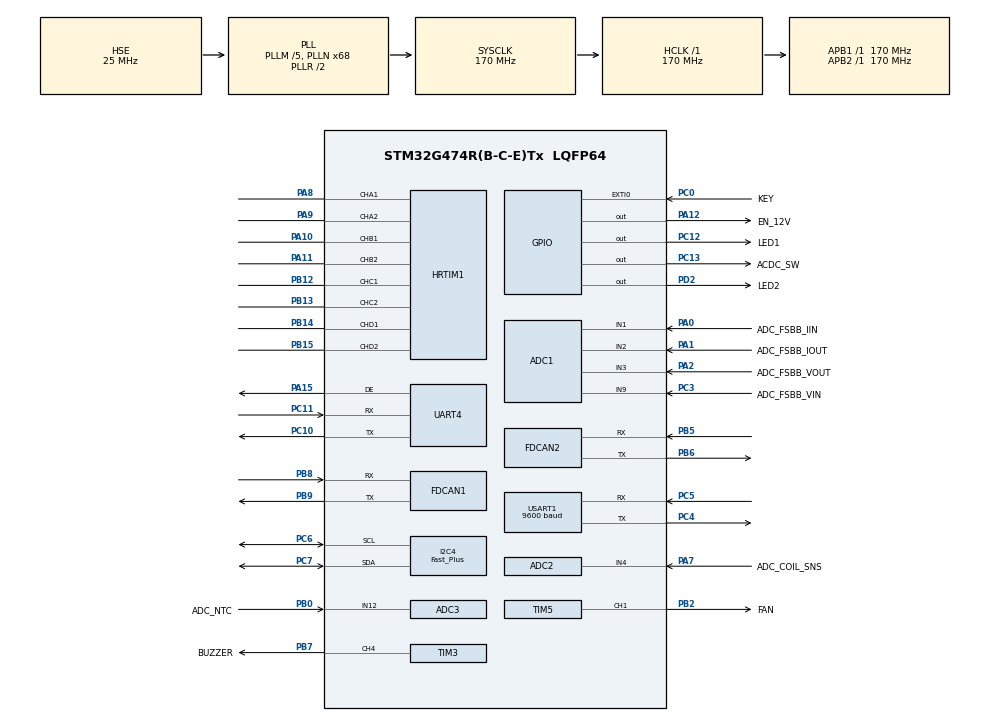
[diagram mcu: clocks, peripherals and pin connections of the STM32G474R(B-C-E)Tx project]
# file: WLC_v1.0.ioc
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ADC1.Channel-0\#ChannelRegularConversion=ADC_CHANNEL_9
ADC1.Channel-1\#ChannelRegularConversion=ADC_CHANNEL_3
ADC1.Channel-2\#ChannelRegularConversion=ADC_CHANNEL_1
ADC1.Channel-3\#ChannelRegularConversion=ADC_CHANNEL_2
ADC1.Channel-4\#ChannelRegularConversion=ADC_CHANNEL_9
ADC1.Channel-5\#ChannelRegularConversion=ADC_CHANNEL_3
ADC1.Channel-6\#ChannelRegularConversion=ADC_CHANNEL_1
ADC1.Channel-7\#ChannelRegularConversion=ADC_CHANNEL_2
ADC1.ContinuousConvMode=ENABLE
ADC1.DMAContinuousRequests=ENABLE
ADC1.EOCSelection=ADC_EOC_SEQ_CONV
ADC1.ExternalTrigConv=ADC_EXTERNALTRIG_HRTIM_TRG3
ADC1.ExternalTrigConvEdge=ADC_EXTERNALTRIGCONVEDGE_RISINGFALLING
ADC1.NbrOfConversion=8
ADC1.NbrOfConversionFlag=1
ADC1.OffsetNumber-0\#ChannelRegularConversion=ADC_OFFSET_NONE
ADC1.OffsetNumber-1\#ChannelRegularConversion=ADC_OFFSET_NONE
ADC1.OffsetNumber-2\#ChannelRegularConversion=ADC_OFFSET_NONE
ADC1.OffsetNumber-3\#ChannelRegularConversion=ADC_OFFSET_NONE
ADC1.OffsetNumber-4\#ChannelRegularConversion=ADC_OFFSET_NONE
ADC1.OffsetNumber-5\#ChannelRegularConversion=ADC_OFFSET_NONE
ADC1.OffsetNumber-6\#ChannelRegularConversion=ADC_OFFSET_NONE
ADC1.OffsetNumber-7\#ChannelRegularConversion=ADC_OFFSET_NONE
ADC1.Overrun=ADC_OVR_DATA_OVERWRITTEN
ADC1.OversamplingMode=ENABLE
ADC1.Rank-0\#ChannelRegularConversion=1
ADC1.Rank-1\#ChannelRegularConversion=2
ADC1.Rank-2\#ChannelRegularConversion=3
ADC1.Rank-3\#ChannelRegularConversion=4
ADC1.Rank-4\#ChannelRegularConversion=5
ADC1.Rank-5\#ChannelRegularConversion=6
ADC1.Rank-6\#ChannelRegularConversion=7
ADC1.Rank-7\#ChannelRegularConversion=8
ADC1.Ratio=ADC_OVERSAMPLING_RATIO_16
ADC1.SamplingTime-0\#ChannelRegularConversion=ADC_SAMPLETIME_2CYCLES_5
ADC1.SamplingTime-1\#ChannelRegularConversion=ADC_SAMPLETIME_2CYCLES_5
ADC1.SamplingTime-2\#ChannelRegularConversion=ADC_SAMPLETIME_2CYCLES_5
ADC1.SamplingTime-3\#ChannelRegularConversion=ADC_SAMPLETIME_2CYCLES_5
ADC1.SamplingTime-4\#ChannelRegularConversion=ADC_SAMPLETIME_2CYCLES_5
ADC1.SamplingTime-5\#ChannelRegularConversion=ADC_SAMPLETIME_2CYCLES_5
ADC1.SamplingTime-6\#ChannelRegularConversion=ADC_SAMPLETIME_2CYCLES_5
ADC1.SamplingTime-7\#ChannelRegularConversion=ADC_SAMPLETIME_2CYCLES_5
ADC1.master=1
ADC2.Channel-0\#ChannelRegularConversion=ADC_CHANNEL_4
ADC2.Channel-1\#ChannelRegularConversion=ADC_CHANNEL_4
ADC2.ContinuousConvMode=ENABLE
ADC2.DMAContinuousRequests=ENABLE
ADC2.ExternalTrigConv=ADC_EXTERNALTRIG_HRTIM_TRG3
ADC2.ExternalTrigConvEdge=ADC_EXTERNALTRIGCONVEDGE_RISINGFALLING
ADC2.NbrOfConversion=2
ADC2.NbrOfConversionFlag=1
ADC2.OffsetNumber-0\#ChannelRegularConversion=ADC_OFFSET_NONE
ADC2.OffsetNumber-1\#ChannelRegularConversion=ADC_OFFSET_NONE
ADC2.Overrun=ADC_OVR_DATA_OVERWRITTEN
ADC2.OversamplingMode=ENABLE
ADC2.Rank-0\#ChannelRegularConversion=1
ADC2.Rank-1\#ChannelRegularConversion=2
ADC2.Ratio=ADC_OVERSAMPLING_RATIO_16
ADC2.SamplingTime-0\#ChannelRegularConversion=ADC_SAMPLETIME_2CYCLES_5
ADC2.SamplingTime-1\#ChannelRegularConversion=ADC_SAMPLETIME_2CYCLES_5
ADC3.Channel-0\#ChannelRegularConversion=ADC_CHANNEL_12
ADC3.Channel-1\#ChannelRegularConversion=ADC_CHANNEL_12
ADC3.ContinuousConvMode=ENABLE
ADC3.DMAContinuousRequests=ENABLE
ADC3.EOCSelection=ADC_EOC_SEQ_CONV
ADC3.ExternalTrigConv=ADC_EXTERNALTRIG_HRTIM_TRG3
ADC3.ExternalTrigConvEdge=ADC_EXTERNALTRIGCONVEDGE_RISINGFALLING
ADC3.NbrOfConversion=2
ADC3.NbrOfConversionFlag=1
ADC3.OffsetNumber-0\#ChannelRegularConversion=ADC_OFFSET_NONE
ADC3.OffsetNumber-1\#ChannelRegularConversion=ADC_OFFSET_NONE
ADC3.Overrun=ADC_OVR_DATA_OVERWRITTEN
ADC3.OversamplingMode=ENABLE
ADC3.Rank-0\#ChannelRegularConversion=1
ADC3.Rank-1\#ChannelRegularConversion=2
ADC3.Ratio=ADC_OVERSAMPLING_RATIO_16
ADC3.SamplingTime-0\#ChannelRegularConversion=ADC_SAMPLETIME_2CYCLES_5
ADC3.SamplingTime-1\#ChannelRegularConversion=ADC_SAMPLETIME_2CYCLES_5
ADC3.master=1
Dma.ADC1.0.Direction=DMA_PERIPH_TO_MEMORY
Dma.ADC1.0.EventEnable=DISABLE
Dma.ADC1.0.Instance=DMA1_Channel1
Dma.ADC1.0.MemDataAlignment=DMA_MDATAALIGN_HALFWORD
Dma.ADC1.0.MemInc=DMA_MINC_ENABLE
Dma.ADC1.0.Mode=DMA_CIRCULAR
Dma.ADC1.0.PeriphDataAlignment=DMA_PDATAALIGN_HALFWORD
Dma.ADC1.0.PeriphInc=DMA_PINC_DISABLE
Dma.ADC1.0.Polarity=HAL_DMAMUX_REQ_GEN_RISING
Dma.ADC1.0.Priority=DMA_PRIORITY_VERY_HIGH
Dma.ADC1.0.RequestNumber=1
Dma.ADC1.0.SignalID=NONE
Dma.ADC1.0.SyncEnable=DISABLE
Dma.ADC1.0.SyncPolarity=HAL_DMAMUX_SYNC_NO_EVENT
Dma.ADC1.0.SyncRequestNumber=1
Dma.ADC1.0.SyncSignalID=NONE
Dma.ADC2.2.Direction=DMA_PERIPH_TO_MEMORY
Dma.ADC2.2.EventEnable=DISABLE
Dma.ADC2.2.Instance=DMA1_Channel3
Dma.ADC2.2.MemDataAlignment=DMA_MDATAALIGN_HALFWORD
Dma.ADC2.2.MemInc=DMA_MINC_ENABLE
Dma.ADC2.2.Mode=DMA_CIRCULAR
Dma.ADC2.2.PeriphDataAlignment=DMA_PDATAALIGN_HALFWORD
Dma.ADC2.2.PeriphInc=DMA_PINC_DISABLE
Dma.ADC2.2.Polarity=HAL_DMAMUX_REQ_GEN_RISING
Dma.ADC2.2.Priority=DMA_PRIORITY_VERY_HIGH
Dma.ADC2.2.RequestNumber=1
Dma.ADC2.2.SignalID=NONE
Dma.ADC2.2.SyncEnable=DISABLE
Dma.ADC2.2.SyncPolarity=HAL_DMAMUX_SYNC_NO_EVENT
Dma.ADC2.2.SyncRequestNumber=1
Dma.ADC2.2.SyncSignalID=NONE
Dma.ADC3.1.Direction=DMA_PERIPH_TO_MEMORY
Dma.ADC3.1.EventEnable=DISABLE
Dma.ADC3.1.Instance=DMA1_Channel2
Dma.ADC3.1.MemDataAlignment=DMA_MDATAALIGN_HALFWORD
Dma.ADC3.1.MemInc=DMA_MINC_ENABLE
Dma.ADC3.1.Mode=DMA_CIRCULAR
Dma.ADC3.1.PeriphDataAlignment=DMA_PDATAALIGN_HALFWORD
Dma.ADC3.1.PeriphInc=DMA_PINC_DISABLE
Dma.ADC3.1.Polarity=HAL_DMAMUX_REQ_GEN_RISING
Dma.ADC3.1.Priority=DMA_PRIORITY_LOW
Dma.ADC3.1.RequestNumber=1
Dma.ADC3.1.SignalID=NONE
Dma.ADC3.1.SyncEnable=DISABLE
Dma.ADC3.1.SyncPolarity=HAL_DMAMUX_SYNC_NO_EVENT
Dma.ADC3.1.SyncRequestNumber=1
Dma.ADC3.1.SyncSignalID=NONE
Dma.Request0=ADC1
Dma.Request1=ADC3
Dma.Request2=ADC2
FDCAN1.CalculateBaudRateNominal=3541666
FDCAN1.CalculateTimeBitNominal=282
FDCAN1.CalculateTimeQuantumNominal=94.11764705882354
FDCAN2.CalculateBaudRateNominal=3541666
FDCAN2.CalculateTimeBitNominal=282
FDCAN2.CalculateTimeQuantumNominal=94.11764705882354
HRTIM1.ADCTrigger1_Source1=HRTIM_ADCTRIGGEREVENT13_MASTER_CMP1
HRTIM1.ADCTrigger3_Source1=HRTIM_ADCTRIGGEREVENT13_MASTER_CMP3
HRTIM1.ADCTrigger_Id1=HRTIM_ADCTRIGGER_1
HRTIM1.ADCTrigger_Id2=__NULL
HRTIM1.ADCTrigger_Id3=HRTIM_ADCTRIGGER_3
HRTIM1.CompareUnit1-MasterTimer=HRTIM_COMPAREUNIT_1
HRTIM1.CompareUnit1-Output_TA1TA2=HRTIM_COMPAREUNIT_1
HRTIM1.CompareUnit1-Output_TB1TB2=HRTIM_COMPAREUNIT_1
HRTIM1.CompareUnit1-Output_TC1TC2=HRTIM_COMPAREUNIT_1
HRTIM1.CompareUnit1-Output_TD1TD2=HRTIM_COMPAREUNIT_1
HRTIM1.CompareUnit2-MasterTimer=__NULL
HRTIM1.CompareUnit2-Output_TA1TA2=__NULL
HRTIM1.CompareUnit2-Output_TB1TB2=HRTIM_COMPAREUNIT_2
HRTIM1.CompareUnit2-Output_TC1TC2=HRTIM_COMPAREUNIT_2
HRTIM1.CompareUnit2-Output_TD1TD2=__NULL
HRTIM1.CompareUnit3-MasterTimer=HRTIM_COMPAREUNIT_3
HRTIM1.CompareUnit3-Output_TA1TA2=HRTIM_COMPAREUNIT_3
HRTIM1.CompareUnit3-Output_TB1TB2=HRTIM_COMPAREUNIT_3
HRTIM1.CompareUnit3-Output_TC1TC2=HRTIM_COMPAREUNIT_3
HRTIM1.CompareUnit3-Output_TD1TD2=HRTIM_COMPAREUNIT_3
HRTIM1.CompareUnit4-MasterTimer=__NULL
HRTIM1.CompareUnit4-Output_TD1TD2=__NULL
HRTIM1.CompareValue1-MasterTimer=0
HRTIM1.CompareValue1-Output_TC1TC2=0xFFDF
HRTIM1.CompareValue1-Output_TD1TD2=0xFFDF
HRTIM1.CompareValue2-Output_TB1TB2=PERIOD_FSBB / 2
HRTIM1.CompareValue2-Output_TC1TC2=PERIOD_LCC/2
HRTIM1.CompareValue3-MasterTimer=PERIOD_MASTERTIMER / 2
HRTIM1.CompareValue3-Output_TB1TB2=0xFFDF
HRTIM1.DeadTimeInsertion-Output_TA1TA2=HRTIM_TIMDEADTIMEINSERTION_ENABLED
HRTIM1.DeadTimeInsertion-Output_TB1TB2=HRTIM_TIMDEADTIMEINSERTION_ENABLED
HRTIM1.DeadTimeInsertion-Output_TC1TC2=HRTIM_TIMDEADTIMEINSERTION_ENABLED
HRTIM1.DeadTimeInsertion-Output_TD1TD2=HRTIM_TIMDEADTIMEINSERTION_ENABLED
HRTIM1.FallingValue-Output_TA1TA2=DeathTime_FSBB
HRTIM1.FallingValue-Output_TB1TB2=DeathTime_FSBB
HRTIM1.FallingValue-Output_TC1TC2=DeathTime_LCC
HRTIM1.FallingValue-Output_TD1TD2=DeathTime_LCC
HRTIM1.FaultLevel1-Output_TC1TC2=HRTIM_OUTPUTFAULTLEVEL_INACTIVE
HRTIM1.FaultLevel1-Output_TD1TD2=HRTIM_OUTPUTFAULTLEVEL_INACTIVE
HRTIM1.FaultLevel2-Output_TC1TC2=HRTIM_OUTPUTFAULTLEVEL_INACTIVE
HRTIM1.FaultLevel2-Output_TD1TD2=HRTIM_OUTPUTFAULTLEVEL_INACTIVE
HRTIM1.InterruptRequests1_Master=HRTIM_MASTER_IT_MREP
HRTIM1.NumberADCTriggerSource1=1
HRTIM1.NumberADCTriggerSource3=1
HRTIM1.NumberFaultEnable-Output_TC1TC2=0
HRTIM1.NumberFaultEnable-Output_TD1TD2=0
HRTIM1.NumberInterruptRequests-Output_TC1TC2=0
HRTIM1.NumberInterruptRequests_Master-MasterTimer=1
HRTIM1.NumberResetSource1-Output_TA1TA2=1
HRTIM1.NumberResetSource1-Output_TB1TB2=1
HRTIM1.NumberResetSource1-Output_TC1TC2=1
HRTIM1.NumberResetSource1-Output_TD1TD2=1
HRTIM1.NumberResetSource2_TC=0
HRTIM1.NumberResetTrigger-Output_TA1TA2=1
HRTIM1.NumberResetTrigger-Output_TB1TB2=1
HRTIM1.NumberResetTrigger-Output_TC1TC2=1
HRTIM1.NumberResetTrigger-Output_TD1TD2=1
HRTIM1.NumberSetSource1-Output_TA1TA2=1
HRTIM1.NumberSetSource1-Output_TB1TB2=1
HRTIM1.NumberSetSource1-Output_TC1TC2=1
HRTIM1.NumberSetSource1-Output_TD1TD2=1
HRTIM1.NumberUpdateTrigger-Output_TA1TA2=1
HRTIM1.NumberUpdateTrigger-Output_TC1TC2=1
HRTIM1.NumberUpdateTrigger-Output_TD1TD2=1
HRTIM1.Periode_MASTER=PERIOD_MASTERTIMER
HRTIM1.Periode_TA=PERIOD_FSBB
HRTIM1.Periode_TB=PERIOD_FSBB
HRTIM1.Periode_TC=PERIOD_LCC
HRTIM1.Periode_TD=PERIOD_LCC
HRTIM1.Polarity1-Output_TA1TA2=HRTIM_OUTPUTPOLARITY_HIGH
HRTIM1.Polarity1-Output_TC1TC2=HRTIM_OUTPUTPOLARITY_HIGH
HRTIM1.Polarity1-Output_TD1TD2=HRTIM_OUTPUTPOLARITY_HIGH
HRTIM1.Polarity2-Output_TC1TC2=HRTIM_OUTPUTPOLARITY_HIGH
HRTIM1.Polarity2-Output_TD1TD2=HRTIM_OUTPUTPOLARITY_HIGH
HRTIM1.PreloadEnable-MasterTimer=HRTIM_PRELOAD_ENABLED
HRTIM1.PreloadEnable-Output_TA1TA2=HRTIM_PRELOAD_ENABLED
HRTIM1.PreloadEnable-Output_TB1TB2=HRTIM_PRELOAD_ENABLED
HRTIM1.PreloadEnable-Output_TC1TC2=HRTIM_PRELOAD_ENABLED
HRTIM1.PreloadEnable-Output_TD1TD2=HRTIM_PRELOAD_ENABLED
HRTIM1.ReSyncUpdate-Output_TC1TC2=HRTIM_TIMERESYNC_UPDATE_CONDITIONAL
HRTIM1.RepetitionCounter-MasterTimer=0
HRTIM1.RepetitionUpdate-MasterTimer=HRTIM_UPDATEONREPETITION_ENABLED
HRTIM1.RepetitionUpdate-Output_TA1TA2=HRTIM_UPDATEONREPETITION_ENABLED
HRTIM1.RepetitionUpdate-Output_TC1TC2=HRTIM_UPDATEONREPETITION_ENABLED
HRTIM1.RepetitionUpdate-Output_TD1TD2=HRTIM_UPDATEONREPETITION_ENABLED
HRTIM1.ResetOutput1_Source1-Output_TA1TA2=HRTIM_OUTPUTRESET_TIMCMP3
HRTIM1.ResetOutput1_Source1-Output_TB1TB2=HRTIM_OUTPUTRESET_TIMCMP3
HRTIM1.ResetOutput1_Source1-Output_TC1TC2=HRTIM_OUTPUTRESET_TIMCMP1
HRTIM1.ResetOutput1_Source1-Output_TD1TD2=HRTIM_OUTPUTRESET_TIMCMP1
HRTIM1.ResetTrigger1-Output_TA1TA2=HRTIM_TIMRESETTRIGGER_MASTER_CMP1
HRTIM1.ResetTrigger1-Output_TB1TB2=HRTIM_TIMRESETTRIGGER_MASTER_CMP1
HRTIM1.ResetTrigger1-Output_TC1TC2=HRTIM_TIMRESETTRIGGER_MASTER_CMP1
HRTIM1.ResetTrigger1-Output_TD1TD2=HRTIM_TIMRESETTRIGGER_OTHER3_CMP2
HRTIM1.ResetUpdate-Output_TA1TA2=HRTIM_TIMUPDATEONRESET_ENABLED
HRTIM1.ResetUpdate-Output_TB1TB2=HRTIM_TIMUPDATEONRESET_ENABLED
HRTIM1.ResetUpdate-Output_TC1TC2=HRTIM_TIMUPDATEONRESET_DISABLED
HRTIM1.ResetUpdate-Output_TD1TD2=HRTIM_TIMUPDATEONRESET_DISABLED
HRTIM1.RisingValue-Output_TA1TA2=DeathTime_FSBB
HRTIM1.RisingValue-Output_TB1TB2=DeathTime_FSBB
HRTIM1.RisingValue-Output_TC1TC2=DeathTime_LCC
HRTIM1.RisingValue-Output_TD1TD2=DeathTime_LCC
HRTIM1.SetOutput1_Source1-Output_TA1TA2=HRTIM_OUTPUTSET_TIMCMP1
HRTIM1.SetOutput1_Source1-Output_TB1TB2=HRTIM_OUTPUTSET_TIMCMP1
HRTIM1.SetOutput1_Source1-Output_TC1TC2=HRTIM_OUTPUTSET_TIMCMP3
HRTIM1.SetOutput1_Source1-Output_TD1TD2=HRTIM_OUTPUTSET_TIMCMP3
HRTIM1.SwapC=__NULL
HRTIM1.UpdateTrigger1-Output_TA1TA2=HRTIM_TIMUPDATETRIGGER_MASTER
HRTIM1.UpdateTrigger1-Output_TC1TC2=HRTIM_TIMUPDATETRIGGER_MASTER
HRTIM1.UpdateTrigger1-Output_TD1TD2=HRTIM_TIMUPDATETRIGGER_MASTER
HRTIM1.postscaler1=1
HRTIM1.postscaler3=10-1
I2C4.Analog_Filter=I2C_ANALOGFILTER_ENABLE
I2C4.I2C_Speed_Mode=I2C_Fast_Plus
I2C4.Timing=0x4052060F
Mcu.Family=STM32G4
Mcu.Name=STM32G474R(B-C-E)Tx
Mcu.Package=LQFP64
Mcu.UserConstants=PERIOD_LCC,47418;PERIOD_FSBB,27200;PERIOD_MASTERTIMER,13600;DeathTime_LCC,50;DeathTime_FSBB,30
NVIC.ADC1_2_IRQn=true\:0\:0\:false\:false\:true\:true\:true\:true
NVIC.ADC3_IRQn=true\:0\:0\:false\:false\:true\:true\:true\:true
NVIC.DMA1_Channel1_IRQn=true\:0\:0\:false\:false\:true\:false\:true\:true
NVIC.DMA1_Channel2_IRQn=true\:0\:0\:false\:false\:true\:false\:true\:true
NVIC.DMA1_Channel3_IRQn=true\:0\:0\:false\:false\:true\:false\:true\:true
NVIC.EXTI0_IRQn=true\:0\:0\:false\:false\:true\:true\:true\:true
NVIC.FDCAN2_IT0_IRQn=true\:0\:0\:false\:false\:true\:true\:true\:true
NVIC.FDCAN2_IT1_IRQn=true\:0\:0\:false\:false\:true\:true\:true\:true
NVIC.HRTIM1_Master_IRQn=true\:0\:0\:false\:false\:true\:true\:true\:true
NVIC.PriorityGroup=NVIC_PRIORITYGROUP_4
NVIC.TIM6_DAC_IRQn=true\:0\:0\:false\:false\:true\:true\:true\:true
NVIC.TIM7_DAC_IRQn=true\:0\:0\:false\:false\:true\:true\:true\:true
NVIC.USART1_IRQn=true\:0\:0\:false\:false\:true\:true\:true\:true
PA0.GPIO_Label=ADC_FSBB_IIN
PA0.Mode=IN1-Single-Ended
PA0.Signal=ADC1_IN1
PA1.GPIO_Label=ADC_FSBB_IOUT
PA1.Mode=IN2-Single-Ended
PA1.Signal=ADC1_IN2
PA10.GPIO_PuPd=GPIO_PULLDOWN
PA10.Mode=Output_TB1TB2
PA10.Signal=HRTIM1_CHB1
PA11.GPIO_PuPd=GPIO_PULLDOWN
PA11.Mode=Output_TB1TB2
PA11.Signal=HRTIM1_CHB2
PA12.GPIO_Label=EN_12V
PA12.GPIO_ModeDefaultOutputPP=GPIO_MODE_OUTPUT_OD
PA12.GPIO_PuPd=GPIO_NOPULL
PA12.PinState=GPIO_PIN_SET
PA12.Signal=GPIO_Output
PA13.Mode=Serial_Wire
PA13.Signal=SYS_JTMS-SWDIO
PA14.Mode=Serial_Wire
PA14.Signal=SYS_JTCK-SWCLK
PA15.Mode=Hardware Flow Control (RS485)
PA15.Signal=UART4_DE
PA2.GPIO_Label=ADC_FSBB_VOUT
PA2.Mode=IN3-Single-Ended
PA2.Signal=ADC1_IN3
PA7.GPIO_Label=ADC_COIL_SNS
PA7.Mode=IN4-Single-Ended
PA7.Signal=ADC2_IN4
PA8.GPIO_PuPd=GPIO_PULLDOWN
PA8.Mode=Output_TA1TA2
PA8.Signal=HRTIM1_CHA1
PA9.GPIO_PuPd=GPIO_PULLDOWN
PA9.Mode=Output_TA1TA2
PA9.Signal=HRTIM1_CHA2
PB0.GPIO_Label=ADC_NTC
PB0.Mode=IN12-Single-Ended
PB0.Signal=ADC3_IN12
PB12.GPIO_PuPd=GPIO_PULLDOWN
PB12.Mode=Output_TC1TC2
PB12.Signal=HRTIM1_CHC1
PB13.GPIO_PuPd=GPIO_PULLDOWN
PB13.Mode=Output_TC1TC2
PB13.Signal=HRTIM1_CHC2
PB14.GPIO_PuPd=GPIO_PULLDOWN
PB14.Mode=Output_TD1TD2
PB14.Signal=HRTIM1_CHD1
PB15.GPIO_PuPd=GPIO_PULLDOWN
PB15.Mode=Output_TD1TD2
PB15.Signal=HRTIM1_CHD2
PB2.GPIO_Label=FAN
PB2.Signal=S_TIM5_CH1
PB5.Mode=FDCAN_Activate
PB5.Signal=FDCAN2_RX
PB6.Mode=FDCAN_Activate
PB6.Signal=FDCAN2_TX
PB7.GPIO_Label=BUZZER
PB7.Signal=S_TIM3_CH4
PB8-BOOT0.Mode=FDCAN_Activate
PB8-BOOT0.Signal=FDCAN1_RX
PB9.Mode=FDCAN_Activate
PB9.Signal=FDCAN1_TX
PC0.GPIO_Label=KEY
PC0.GPIO_ModeDefaultEXTI=GPIO_MODE_IT_FALLING
PC0.GPIO_PuPd=GPIO_PULLUP
PC0.Signal=GPXTI0
PC10.Mode=Asynchronous
PC10.Signal=UART4_TX
PC11.Mode=Asynchronous
PC11.Signal=UART4_RX
PC12.GPIO_Label=LED1
PC12.GPIO_ModeDefaultOutputPP=GPIO_MODE_OUTPUT_OD
PC12.GPIO_PuPd=GPIO_PULLUP
PC12.Signal=GPIO_Output
PC13.GPIO_Label=ACDC_SW
PC13.Signal=GPIO_Output
PC3.GPIO_Label=ADC_FSBB_VIN
PC3.Mode=IN9-Single-Ended
PC3.Signal=ADC1_IN9
PC4.Mode=Asynchronous
PC4.Signal=USART1_TX
PC5.Mode=Asynchronous
PC5.Signal=USART1_RX
PC6.Mode=I2C
PC6.Signal=I2C4_SCL
PC7.Mode=I2C
PC7.Signal=I2C4_SDA
PD2.GPIO_Label=LED2
PD2.GPIO_ModeDefaultOutputPP=GPIO_MODE_OUTPUT_OD
PD2.GPIO_PuPd=GPIO_PULLUP
PD2.Signal=GPIO_Output
PF0-OSC_IN.Mode=HSE-External-Oscillator
PF0-OSC_IN.Signal=RCC_OSC_IN
PF1-OSC_OUT.Mode=HSE-External-Oscillator
PF1-OSC_OUT.Signal=RCC_OSC_OUT
ProjectManager.HeapSize=0x2000
ProjectManager.StackSize=0x6000
ProjectManager.TargetToolchain=STM32CubeIDE
RCC.ADC12Freq_Value=170000000
RCC.ADC345Freq_Value=170000000
RCC.AHBFreq_Value=170000000
RCC.APB1Freq_Value=170000000
RCC.APB1TimFreq_Value=170000000
RCC.APB2Freq_Value=170000000
RCC.APB2TimFreq_Value=170000000
RCC.CK48CLockSelection=RCC_USBCLKSOURCE_HSI48
RCC.CortexFreq_Value=170000000
RCC.EXTERNAL_CLOCK_VALUE=12288000
RCC.HCLKFreq_Value=170000000
RCC.HSE_VALUE=25000000
RCC.HSI48_VALUE=48000000
RCC.HSI_VALUE=16000000
RCC.LSE_VALUE=32768
RCC.PLLM=RCC_PLLM_DIV5
RCC.PLLN=68
RCC.PLLSourceVirtual=RCC_PLLSOURCE_HSE
RCC.SYSCLKFreq_VALUE=170000000
RCC.SYSCLKSource=RCC_SYSCLKSOURCE_PLLCLK
RCC.USBFreq_Value=48000000
RCC.VCOOutputFreq_Value=340000000
SH.S_TIM3_CH4.0=TIM3_CH4,PWM Generation4 CH4
SH.S_TIM5_CH1.0=TIM5_CH1,PWM Generation1 CH1
TIM3.Channel-PWM\ Generation4\ CH4=TIM_CHANNEL_4
TIM3.PeriodNoDither=3000-1
TIM3.Prescaler=170
TIM5.AutoReloadPreload=TIM_AUTORELOAD_PRELOAD_ENABLE
TIM5.Channel-PWM\ Generation1\ CH1=TIM_CHANNEL_1
TIM5.PeriodNoDither=1000-1
TIM5.Prescaler=170
TIM6.AutoReloadPreload=TIM_AUTORELOAD_PRELOAD_ENABLE
TIM6.PeriodNoDither=1000-1
TIM6.Prescaler=170-1
TIM7.AutoReloadPreload=TIM_AUTORELOAD_PRELOAD_ENABLE
TIM7.PeriodNoDither=10000-1
TIM7.Prescaler=170-1
USART1.BaudRate=9600
USART1.VirtualMode-Asynchronous=VM_ASYNC
VP_FMAC_VS_FMAC.Mode=FMAC_Activate
VP_HRTIM1_VS_hrtimMasterTimerNoOutput.Mode=MasterTimer
VP_SYS_VS_DBSignals.Mode=DisableDeadBatterySignals
VP_TIM16_VS_ClockSourceINT.Mode=Enable_Timer
VP_TIM3_VS_ClockSourceINT.Mode=Internal
VP_TIM5_VS_ClockSourceINT.Mode=Internal
VP_TIM6_VS_ClockSourceINT.Mode=Enable_Timer
VP_TIM7_VS_ClockSourceINT.Mode=Enable_Timer
board=custom

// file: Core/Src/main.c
/* USER CODE BEGIN Header */
/**
 ******************************************************************************
 * @file           : main.c
 * @brief          : Main program body
 ******************************************************************************
 * @attention
 *
 * Copyright (c) 2025 STMicroelectronics.
 * All rights reserved.
 *
 * This software is licensed under terms that can be found in the LICENSE file
 * in the root directory of this software component.
 * If no LICENSE file comes with this software, it is provided AS-IS.
 *
 ******************************************************************************
 */
/* USER CODE END Header */
#include "main.h"
#include "adc.h"
#include "dma.h"
#include "fdcan.h"
#include "fmac.h"
#include "hrtim.h"
#include "i2c.h"
#include "tim.h"
#include "usart.h"
#include "gpio.h"

/* USER CODE BEGIN Includes */
#include "buzzer.h"
#include "oled.h"
#include "wlc_ctrl.h"
/* USER CODE END Includes */

void SystemClock_Config(void);

int main(void)
{

  /* MCU Configuration--------------------------------------------------------*/

  /* Reset of all peripherals, Initializes the Flash interface and the Systick. */
  HAL_Init();

  /* Configure the system clock */
  SystemClock_Config();

  /* Initialize all configured peripherals */
  MX_GPIO_Init();
  MX_DMA_Init();
  MX_FDCAN1_Init();
  MX_FDCAN2_Init();
  MX_HRTIM1_Init();
  MX_FMAC_Init();
  MX_TIM16_Init();
  MX_ADC1_Init();
  MX_I2C4_Init();
  MX_TIM3_Init();
  MX_USART1_UART_Init();
  MX_TIM6_Init();
  MX_ADC3_Init();
  MX_UART4_Init();
  MX_TIM5_Init();
  MX_ADC2_Init();
  MX_TIM7_Init();
  /* USER CODE BEGIN 2 */

    HAL_GPIO_WritePin(EN_12V_GPIO_Port, EN_12V_Pin, GPIO_PIN_SET);

    // HRTIM_PWM_init();
    HAL_Delay(10);
    WLC_CTRL_INIT();

    // OLED_init();
    // OLED_LOGO();
    Buzzer_Startup_Prompting();

  /* USER CODE END 2 */

  /* Infinite loop */
  /* USER CODE BEGIN WHILE */
    while (1) {
        HAL_Delay(114);
        HAL_GPIO_TogglePin(LED1_GPIO_Port, LED1_Pin);
        HAL_Delay(114);
        HAL_GPIO_TogglePin(LED2_GPIO_Port, LED2_Pin);
    /* USER CODE END WHILE */

    }
}

void SystemClock_Config(void)
{
  RCC_OscInitTypeDef RCC_OscInitStruct = {0};
  RCC_ClkInitTypeDef RCC_ClkInitStruct = {0};

  /** Configure the main internal regulator output voltage
  */
  HAL_PWREx_ControlVoltageScaling(PWR_REGULATOR_VOLTAGE_SCALE1_BOOST);

  /** Initializes the RCC Oscillators according to the specified parameters
  * in the RCC_OscInitTypeDef structure.
  */
  RCC_OscInitStruct.OscillatorType = RCC_OSCILLATORTYPE_HSE;
  RCC_OscInitStruct.HSEState = RCC_HSE_ON;
  RCC_OscInitStruct.PLL.PLLState = RCC_PLL_ON;
  RCC_OscInitStruct.PLL.PLLSource = RCC_PLLSOURCE_HSE;
  RCC_OscInitStruct.PLL.PLLM = RCC_PLLM_DIV5;
  RCC_OscInitStruct.PLL.PLLN = 68;
  RCC_OscInitStruct.PLL.PLLP = RCC_PLLP_DIV2;
  RCC_OscInitStruct.PLL.PLLQ = RCC_PLLQ_DIV2;
  RCC_OscInitStruct.PLL.PLLR = RCC_PLLR_DIV2;
  if (HAL_RCC_OscConfig(&RCC_OscInitStruct) != HAL_OK)
  {
    Error_Handler();
  }

  /** Initializes the CPU, AHB and APB buses clocks
  */
  RCC_ClkInitStruct.ClockType = RCC_CLOCKTYPE_HCLK|RCC_CLOCKTYPE_SYSCLK
                              |RCC_CLOCKTYPE_PCLK1|RCC_CLOCKTYPE_PCLK2;
  RCC_ClkInitStruct.SYSCLKSource = RCC_SYSCLKSOURCE_PLLCLK;
  RCC_ClkInitStruct.AHBCLKDivider = RCC_SYSCLK_DIV1;
  RCC_ClkInitStruct.APB1CLKDivider = RCC_HCLK_DIV1;
  RCC_ClkInitStruct.APB2CLKDivider = RCC_HCLK_DIV1;

  if (HAL_RCC_ClockConfig(&RCC_ClkInitStruct, FLASH_LATENCY_4) != HAL_OK)
  {
    Error_Handler();
  }
}

void Error_Handler(void)
{
    __disable_irq();
    while (1) {
    }
}
